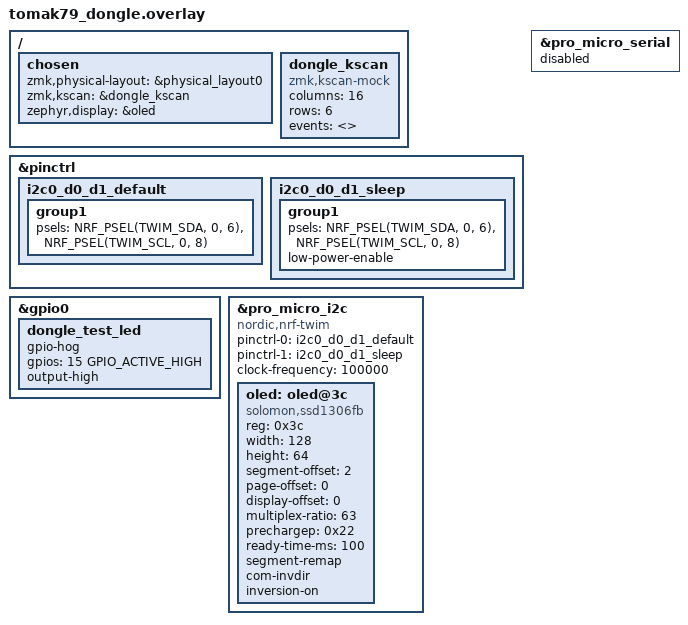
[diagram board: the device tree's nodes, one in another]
#include <behaviors.dtsi>
#include <dt-bindings/zmk/keys.h>
#include "tomak79.dtsi"

/ {
    chosen {
        zmk,physical-layout = &physical_layout0;
        zmk,kscan = &dongle_kscan;
        zephyr,display = &oled;
    };

    dongle_kscan: dongle_kscan {
        compatible = "zmk,kscan-mock";
        status = "okay";
        columns = <16>;
        rows = <6>;
        events = <>;
    };
};

&pinctrl {
    i2c0_d0_d1_default: i2c0_d0_d1_default {
        group1 {
            psels = <NRF_PSEL(TWIM_SDA, 0, 6)>,
                <NRF_PSEL(TWIM_SCL, 0, 8)>;
        };
    };

    i2c0_d0_d1_sleep: i2c0_d0_d1_sleep {
        group1 {
            psels = <NRF_PSEL(TWIM_SDA, 0, 6)>,
                <NRF_PSEL(TWIM_SCL, 0, 8)>;
            low-power-enable;
        };
    };
};

&gpio0 {
    dongle_test_led {
        gpio-hog;
        gpios = <15 GPIO_ACTIVE_HIGH>;
        output-high;
    };
};

&pro_micro_serial {
    status = "disabled";
};

&pro_micro_i2c {
    status = "okay";
    compatible = "nordic,nrf-twim";
    pinctrl-0 = <&i2c0_d0_d1_default>;
    pinctrl-1 = <&i2c0_d0_d1_sleep>;
    pinctrl-names = "default", "sleep";
    clock-frequency = <100000>;

    oled: oled@3c {
        compatible = "solomon,ssd1306fb";
        reg = <0x3c>;
        width = <128>;
        height = <64>;
        segment-offset = <2>;
        page-offset = <0>;
        display-offset = <0>;
        multiplex-ratio = <63>;
        prechargep = <0x22>;
        ready-time-ms = <100>;
        segment-remap;
        com-invdir;
        inversion-on;
    };
};
